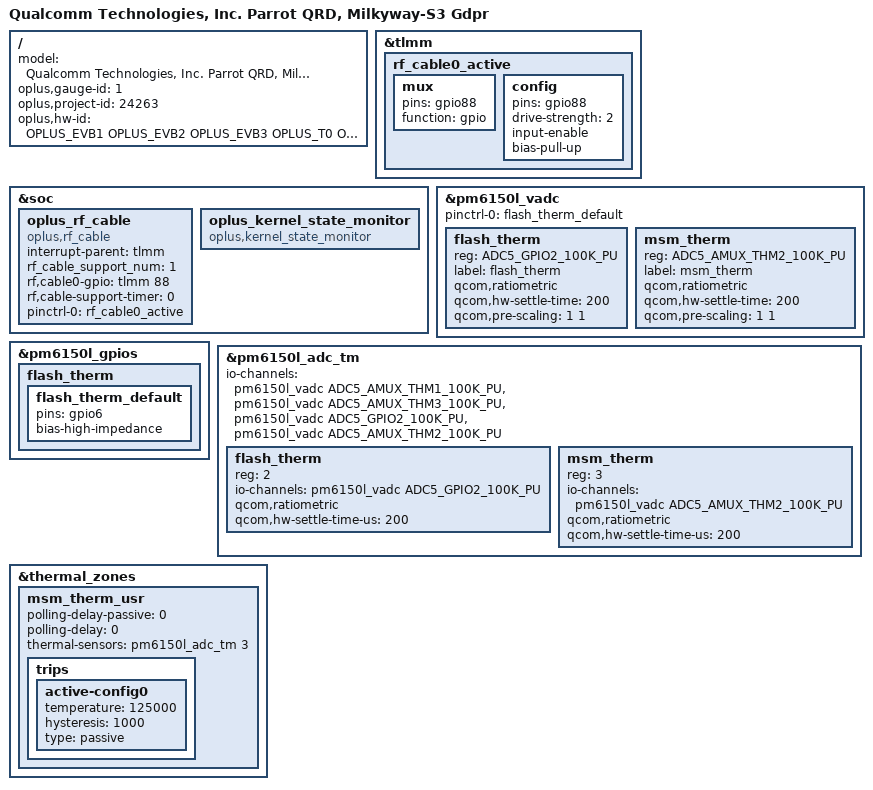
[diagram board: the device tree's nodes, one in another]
/dts-v1/;
/plugin/;
#include <dt-bindings/oplus/hw-id.h>
#include "../qcom/parrot-qrd-overlay.dts"
#include "parrot_overlay_common.dtsi"
#include "milkyways35g_overlay_common.dtsi"
#include "oplus_chg/oplus-chg-milkyway-s3-5g-gdpr.dtsi"
#include "oplus_chg/oplus-chg-milkyway-s3-5g-pps.dtsi"
#include "milkyways35g-24263-esim-sn220e.dts"
#include "nfc/milkyway-s3-5G-nfc-sn220e-thn31f-a.dtsi"

/ {
    model = "Qualcomm Technologies, Inc. Parrot QRD, Milkyway-S3 Gdpr";
    oplus,gauge-id = <1>;//pull down
    oplus,project-id = <24263>;
    oplus,hw-id = <OPLUS_EVB1 OPLUS_EVB2 OPLUS_EVB3 OPLUS_T0 OPLUS_EVT1 OPLUS_EVT2 OPLUS_DVT1 OPLUS_DVT2 OPLUS_PVT1>;
};

&tlmm {
  //#ifdef OPLUS_FEATURE_RF_CABLE_DETECT
  rf_cable0_active: rf_cable0_active {
    mux {
      pins = "gpio88";
      function = "gpio";
    };
    config {
      pins = "gpio88";
      drive-strength = <2>;
      input-enable;
      bias-pull-up;
    };
  };
  //#endif /* OPLUS_FEATURE_RF_CABLE_DETECT */
};

&soc {
  //#ifdef OPLUS_FEATURE_RF_CABLE_DETECT
  oplus_rf_cable {
    compatible = "oplus,rf_cable";
    interrupt-parent = <&tlmm>;
    rf_cable_support_num = <1>;
    rf,cable0-gpio = <&tlmm 88 0>;
    rf,cable-support-timer = <0>;
    pinctrl-names = "rf_cable_active";
    pinctrl-0 = <&rf_cable0_active>;
  };
  //#endif /* OPLUS_FEATURE_RF_CABLE_DETECT */

  oplus_kernel_state_monitor {
    compatible = "oplus,kernel_state_monitor";
  };
};


&pm6150l_vadc {
	/delete-property/ pinctrl-0;
	pinctrl-0 = <&flash_therm_default>;

	/delete-node/ ufs_therm;
	/delete-node/ wide_rfc_therm;
	flash_therm {
		reg = <ADC5_GPIO2_100K_PU>;
		label = "flash_therm";
		qcom,ratiometric;
		qcom,hw-settle-time = <200>;
		qcom,pre-scaling = <1 1>;
	};

	msm_therm {
		reg = <ADC5_AMUX_THM2_100K_PU>;
		label = "msm_therm";
		qcom,ratiometric;
		qcom,hw-settle-time = <200>;
		qcom,pre-scaling = <1 1>;
	};
};

&pm6150l_gpios {
	flash_therm {
		flash_therm_default: flash_therm_default {
			pins = "gpio6";
			bias-high-impedance;
		};
	};
};

&pm6150l_adc_tm {
	/delete-property/ io-channels;
	io-channels = <&pm6150l_vadc ADC5_AMUX_THM1_100K_PU>,
			<&pm6150l_vadc ADC5_AMUX_THM3_100K_PU>,
			<&pm6150l_vadc ADC5_GPIO2_100K_PU>,
			<&pm6150l_vadc ADC5_AMUX_THM2_100K_PU>;

	/delete-node/ ufs_therm;
	/delete-node/ wide_rfc_therm;
	flash_therm {
		reg = <2>;
		io-channels = <&pm6150l_vadc ADC5_GPIO2_100K_PU>;
		qcom,ratiometric;
		qcom,hw-settle-time-us = <200>;
	};

	msm_therm {
		reg = <3>;
		io-channels = <&pm6150l_vadc ADC5_AMUX_THM2_100K_PU>;
		qcom,ratiometric;
		qcom,hw-settle-time-us = <200>;
	};
};

&thermal_zones {
	/delete-node/ sys-therm-1;
	/delete-node/ sys-therm-2;

	msm_therm_usr {
		polling-delay-passive = <0>;
		polling-delay = <0>;
		thermal-sensors = <&pm6150l_adc_tm 3>;
		trips {
			active-config0 {
				temperature = <125000>;
				hysteresis = <1000>;
				type = "passive";
			};
		};
	};
};
